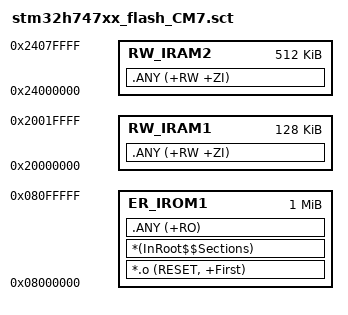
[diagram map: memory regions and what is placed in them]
; *************************************************************
; *** Scatter-Loading Description File generated by uVision ***
; *************************************************************

LR_IROM1 0x08000000 0x00100000  {    ; load region size_region
  ER_IROM1 0x08000000 0x00100000  {  ; load address = execution address
   *.o (RESET, +First)
   *(InRoot$$Sections)
   .ANY (+RO)
  }
  RW_IRAM1 0x20000000 0x00020000{  ; DTCM 128K - RW data
   .ANY (+RW +ZI)
  }
  RW_IRAM2 0x24000000 0x00080000{  ; AXI SRAM (D1) 512K - lwIP pools, heaps, large buffers
   .ANY (+RW +ZI)
  }
}
